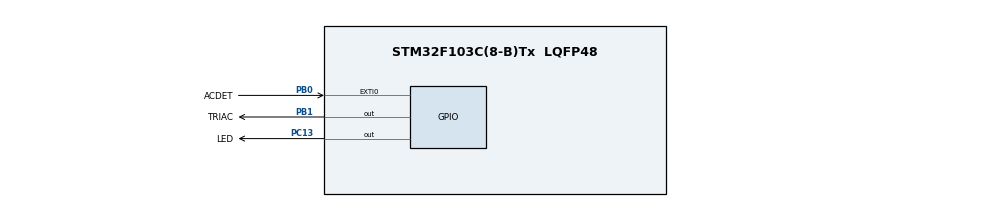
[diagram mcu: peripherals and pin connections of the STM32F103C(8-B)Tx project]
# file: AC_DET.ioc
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Mcu.Family=STM32F1
Mcu.Name=STM32F103C(8-B)Tx
Mcu.Package=LQFP48
NVIC.EXTI0_IRQn=true\:0\:0\:false\:false\:true\:true\:true\:true
NVIC.PriorityGroup=NVIC_PRIORITYGROUP_4
PA13.Mode=Serial_Wire
PA13.Signal=SYS_JTMS-SWDIO
PA14.Mode=Serial_Wire
PA14.Signal=SYS_JTCK-SWCLK
PB0.GPIO_Label=ACDET
PB0.GPIO_ModeDefaultEXTI=GPIO_MODE_IT_FALLING
PB0.Signal=GPXTI0
PB1.GPIO_Label=TRIAC
PB1.GPIO_Speed=GPIO_SPEED_FREQ_HIGH
PB1.Signal=GPIO_Output
PC13-TAMPER-RTC.GPIO_Label=LED
PC13-TAMPER-RTC.GPIO_Speed=GPIO_SPEED_FREQ_HIGH
PC13-TAMPER-RTC.PinState=GPIO_PIN_RESET
PC13-TAMPER-RTC.Signal=GPIO_Output
PD0-OSC_IN.Mode=HSE-External-Oscillator
PD0-OSC_IN.Signal=RCC_OSC_IN
PD1-OSC_OUT.Mode=HSE-External-Oscillator
PD1-OSC_OUT.Signal=RCC_OSC_OUT
ProjectManager.HeapSize=0x200
ProjectManager.StackSize=0x400
ProjectManager.TargetToolchain=STM32CubeIDE
RCC.APB1Freq_Value=8000000
RCC.APB2Freq_Value=8000000
board=custom

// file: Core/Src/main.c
/* USER CODE BEGIN Header */
/**
  ******************************************************************************
  * @file           : main.c
  * @brief          : Main program body
  ******************************************************************************
  * @attention
  *
  * Copyright (c) 2023 STMicroelectronics.
  * All rights reserved.
  *
  * This software is licensed under terms that can be found in the LICENSE file
  * in the root directory of this software component.
  * If no LICENSE file comes with this software, it is provided AS-IS.
  *
  ******************************************************************************
  */
/* USER CODE END Header */
#include "main.h"

/* USER CODE BEGIN PM */
#define LED_ON 0
#define LED_OFF 1
/* USER CODE END PM */

/* USER CODE BEGIN PV */
//uint32_t tgKich = 0;
volatile uint8_t flag = 0;
uint8_t tgDelayTaoGocKich = 0; // giá trị không được vượt qá 10ms
/* USER CODE END PV */

void SystemClock_Config(void);
static void MX_GPIO_Init(void);
/* USER CODE BEGIN PFP */
void HAL_GPIO_EXTI_Callback(uint16_t GPIO_Pin);
void TaoXungKickTriac();
//void DelayFunction(uint32_t tgDelay, void(*Function)());
/* USER CODE END PFP */

int main(void)
{
  /* USER CODE BEGIN 1 */
  uint32_t tgDelayTaoXung = 0;
  uint8_t ledStatus = 0;
  /* USER CODE END 1 */

  /* MCU Configuration--------------------------------------------------------*/

  /* Reset of all peripherals, Initializes the Flash interface and the Systick. */
  HAL_Init();

  /* Configure the system clock */
  SystemClock_Config();

  /* Initialize all configured peripherals */
  MX_GPIO_Init();

  /* Infinite loop */
  /* USER CODE BEGIN WHILE */
  while (1)
  {
	  //tg kích ms
//	  if(flag == 0) {
//		  tgKich = HAL_GetTick();
//	  }
//	  else if(HAL_GetTick() - tgKich >= tgDelayTaoGocKich){
//		  TaoXungKickTriac();
//		  flag = 0;
//	  }
    /* USER CODE END WHILE */

    /* USER CODE BEGIN 3 */
	  if(flag == 1){
//		  HAL_Delay(tgDelayTaoGocKich);
		  // tìm cách delay khúc này =>
		  if(tgDelayTaoGocKich > 0){
			  HAL_GPIO_WritePin(TRIAC_GPIO_Port, TRIAC_Pin, 1);
		  }
		  HAL_Delay(1);
		  HAL_GPIO_WritePin(TRIAC_GPIO_Port, TRIAC_Pin, 0);
		  flag = 0;
	  }
	  if(HAL_GetTick() - tgDelayTaoXung >= 1000){
		  tgDelayTaoXung = HAL_GetTick();
		  ledStatus = ~ledStatus;
		  HAL_GPIO_WritePin(LED_GPIO_Port, LED_Pin, ledStatus);
	  }

  }
  /* USER CODE END 3 */
}

void SystemClock_Config(void)
{
  RCC_OscInitTypeDef RCC_OscInitStruct = {0};
  RCC_ClkInitTypeDef RCC_ClkInitStruct = {0};

  /** Initializes the RCC Oscillators according to the specified parameters
  * in the RCC_OscInitTypeDef structure.
  */
  RCC_OscInitStruct.OscillatorType = RCC_OSCILLATORTYPE_HSI;
  RCC_OscInitStruct.HSIState = RCC_HSI_ON;
  RCC_OscInitStruct.HSICalibrationValue = RCC_HSICALIBRATION_DEFAULT;
  RCC_OscInitStruct.PLL.PLLState = RCC_PLL_NONE;
  if (HAL_RCC_OscConfig(&RCC_OscInitStruct) != HAL_OK)
  {
    Error_Handler();
  }

  /** Initializes the CPU, AHB and APB buses clocks
  */
  RCC_ClkInitStruct.ClockType = RCC_CLOCKTYPE_HCLK|RCC_CLOCKTYPE_SYSCLK
                              |RCC_CLOCKTYPE_PCLK1|RCC_CLOCKTYPE_PCLK2;
  RCC_ClkInitStruct.SYSCLKSource = RCC_SYSCLKSOURCE_HSI;
  RCC_ClkInitStruct.AHBCLKDivider = RCC_SYSCLK_DIV1;
  RCC_ClkInitStruct.APB1CLKDivider = RCC_HCLK_DIV1;
  RCC_ClkInitStruct.APB2CLKDivider = RCC_HCLK_DIV1;

  if (HAL_RCC_ClockConfig(&RCC_ClkInitStruct, FLASH_LATENCY_0) != HAL_OK)
  {
    Error_Handler();
  }
}

static void MX_GPIO_Init(void)
{
  GPIO_InitTypeDef GPIO_InitStruct = {0};

  /* GPIO Ports Clock Enable */
  __HAL_RCC_GPIOC_CLK_ENABLE();
  __HAL_RCC_GPIOD_CLK_ENABLE();
  __HAL_RCC_GPIOB_CLK_ENABLE();
  __HAL_RCC_GPIOA_CLK_ENABLE();

  /*Configure GPIO pin Output Level */
  HAL_GPIO_WritePin(LED_GPIO_Port, LED_Pin, GPIO_PIN_SET);

  /*Configure GPIO pin Output Level */
  HAL_GPIO_WritePin(TRIAC_GPIO_Port, TRIAC_Pin, GPIO_PIN_RESET);

  /*Configure GPIO pin : LED_Pin */
  GPIO_InitStruct.Pin = LED_Pin;
  GPIO_InitStruct.Mode = GPIO_MODE_OUTPUT_PP;
  GPIO_InitStruct.Pull = GPIO_NOPULL;
  GPIO_InitStruct.Speed = GPIO_SPEED_FREQ_HIGH;
  HAL_GPIO_Init(LED_GPIO_Port, &GPIO_InitStruct);

  /*Configure GPIO pin : ACDET_Pin */
  GPIO_InitStruct.Pin = ACDET_Pin;
  GPIO_InitStruct.Mode = GPIO_MODE_IT_FALLING;
  GPIO_InitStruct.Pull = GPIO_NOPULL;
  HAL_GPIO_Init(ACDET_GPIO_Port, &GPIO_InitStruct);

  /*Configure GPIO pin : TRIAC_Pin */
  GPIO_InitStruct.Pin = TRIAC_Pin;
  GPIO_InitStruct.Mode = GPIO_MODE_OUTPUT_PP;
  GPIO_InitStruct.Pull = GPIO_NOPULL;
  GPIO_InitStruct.Speed = GPIO_SPEED_FREQ_HIGH;
  HAL_GPIO_Init(TRIAC_GPIO_Port, &GPIO_InitStruct);

  /* EXTI interrupt init*/
  HAL_NVIC_SetPriority(EXTI0_IRQn, 0, 0);
  HAL_NVIC_EnableIRQ(EXTI0_IRQn);

}

/* USER CODE BEGIN 4 */
void HAL_GPIO_EXTI_Callback(uint16_t GPIO_Pin){
//	HAL_Delay(0); // delay 5ms mất nữa sóng
//	// tạo xung kích cho triac
//	HAL_GPIO_WritePin(TRIAC_GPIO_Port, TRIAC_Pin, 1);
//	HAL_Delay(1);
//	HAL_GPIO_WritePin(TRIAC_GPIO_Port, TRIAC_Pin, 0);
	if(tgDelayTaoGocKich == 0){
		HAL_GPIO_WritePin(TRIAC_GPIO_Port, TRIAC_Pin, 1);
	}
	flag = 1;
}
//void TaoXungKickTriac(){
//	static uint8_t step = 0;
//	static uint32_t T_TRIAC = 0;
//	switch(step){
//	case 0:
//		HAL_GPIO_WritePin(TRIAC_GPIO_Port, TRIAC_Pin, 1);
//		T_TRIAC = HAL_GetTick();
//		step = 1;
//		break;
//	case 1:
//		if(HAL_GetTick() - T_TRIAC >= 1){
//			HAL_GPIO_WritePin(TRIAC_GPIO_Port, TRIAC_Pin, 0);
//			step = 0;
//			flag = 0;
//		}
//	}
//}

//void DelayFunction(uint32_t tgDelay, void(*Function)()){
//	static uint8_t step = 0;
//	static uint32_t T = 0;
//	switch(step){
//	case 0:
//		T = HAL_GetTick();
//		step = 1;
//		break;
//	case 1:
//		if(HAL_GetTick() - T >= tgDelay){
//			Function();
//			step = 0;
//		}
//	}
//}
/* USER CODE END 4 */

void Error_Handler(void)
{
  __disable_irq();
  while (1)
  {
  }
}
